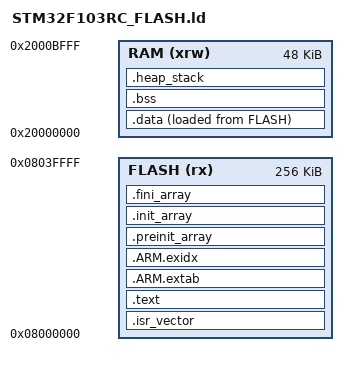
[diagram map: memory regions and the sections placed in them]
ENTRY(Reset_Handler)
MEMORY
{
  FLASH (rx) : ORIGIN = 0x08000000, LENGTH = 256K
  RAM (xrw) : ORIGIN = 0x20000000, LENGTH = 48K
}
_estack = ORIGIN(RAM) + LENGTH(RAM);
_Min_Stack_Size = 0x800;
SECTIONS
{
  .isr_vector : { . = ALIGN(4); KEEP(*(.isr_vector)) } > FLASH
  .text :
  {
    . = ALIGN(4); *(.text*) *(.rodata*) *(.glue_7*)
    KEEP(*(.init)) KEEP(*(.fini))
    . = ALIGN(4);
  } > FLASH
  .ARM.extab (READONLY) : { *(.ARM.extab* .gnu.linkonce.armextab.*) } > FLASH
  .ARM.exidx (READONLY) :
  { __exidx_start = .; *(.ARM.exidx* .gnu.linkonce.armexidx.*) __exidx_end = .; } > FLASH
  .preinit_array (READONLY) :
  { PROVIDE_HIDDEN(__preinit_array_start = .); KEEP(*(.preinit_array*)) PROVIDE_HIDDEN(__preinit_array_end = .); } > FLASH
  .init_array (READONLY) :
  { PROVIDE_HIDDEN(__init_array_start = .); KEEP(*(SORT(.init_array.*))) KEEP(*(.init_array*)) PROVIDE_HIDDEN(__init_array_end = .); } > FLASH
  .fini_array (READONLY) :
  { PROVIDE_HIDDEN(__fini_array_start = .); KEEP(*(SORT(.fini_array.*))) KEEP(*(.fini_array*)) PROVIDE_HIDDEN(__fini_array_end = .); } > FLASH
  _sidata = LOADADDR(.data);
  .data : { . = ALIGN(4); _sdata = .; *(.data*) . = ALIGN(4); _edata = .; } > RAM AT> FLASH
  .bss (NOLOAD) :
  { . = ALIGN(4); _sbss = .; *(.bss*) *(COMMON) . = ALIGN(4); _ebss = .; } > RAM
  .heap_stack (NOLOAD) :
  { . = ALIGN(8); PROVIDE(end = .); PROVIDE(_end = .); . += 0x200; . += 0x800; . = ALIGN(8); } > RAM
  ASSERT(. <= _estack, "STM32F103RC RAM overflow")
}
